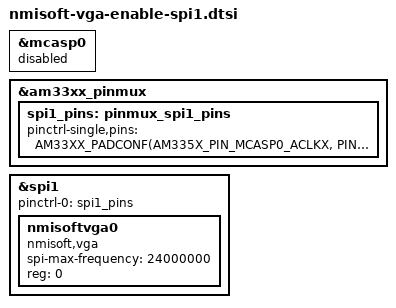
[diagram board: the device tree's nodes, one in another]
&mcasp0 {
	status = "disabled";
};

&am33xx_pinmux {
	spi1_pins: pinmux_spi1_pins {
		pinctrl-single,pins = <
			AM33XX_PADCONF(AM335X_PIN_MCASP0_ACLKX, PIN_OUTPUT, MUX_MODE3)		/* SPI1_SCLK */
			AM33XX_PADCONF(AM335X_PIN_MCASP0_FSX, PIN_INPUT_PULLUP, MUX_MODE3)	/* SPI1_D0 */
			AM33XX_PADCONF(AM335X_PIN_MCASP0_AXR0, PIN_OUTPUT, MUX_MODE3)		/* SPI1_D1 */
			AM33XX_PADCONF(AM335X_PIN_MCASP0_AHCLKR, PIN_OUTPUT, MUX_MODE3)		/* SPI1_CS0 */
		>;
	};
};

&spi1 {
	status = "okay";

	pinctrl-names = "default";
	pinctrl-0 = <&spi1_pins>;

	nmisoftvga0 {
		compatible = "nmisoft,vga";

		spi-max-frequency = <24000000>;
		reg = <0>;
	};
};
